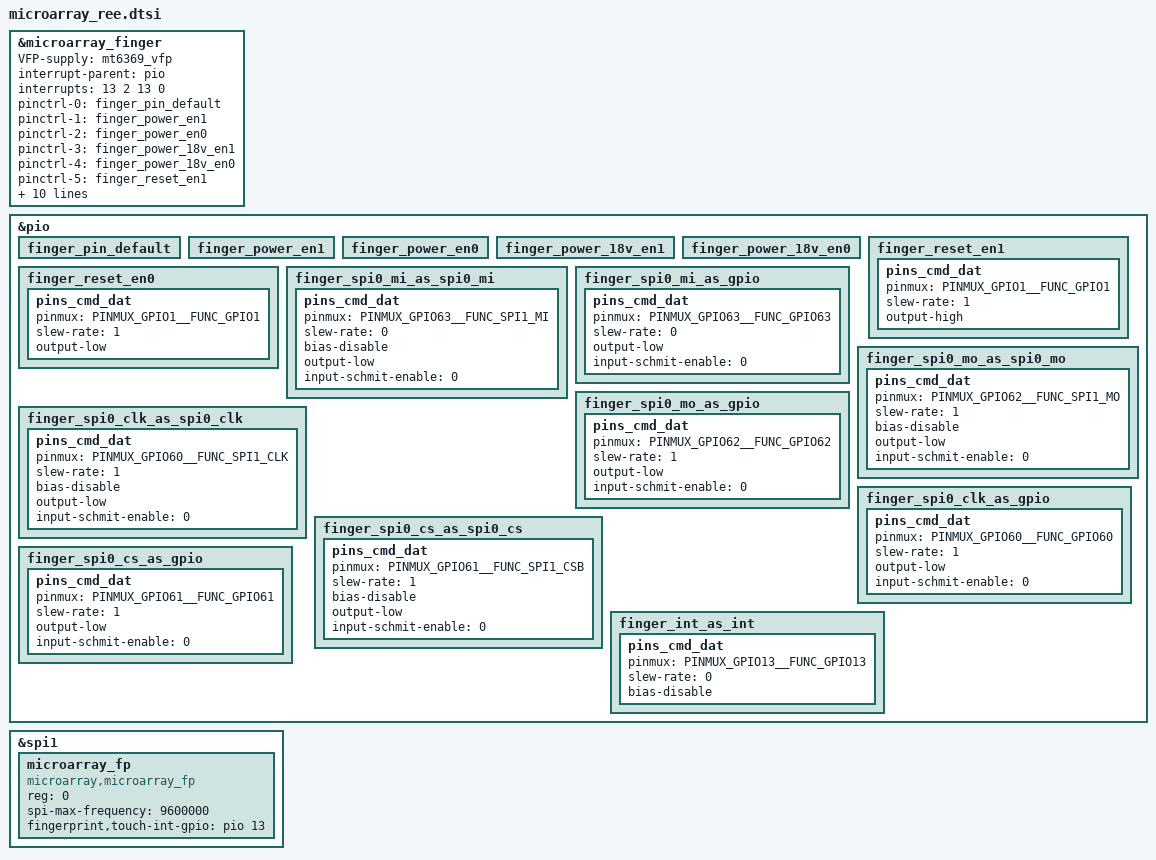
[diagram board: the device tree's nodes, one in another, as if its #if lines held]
#include "../../drv_common.h"

#if PRI_PLATFORM_MT6878
#include "./mt6878/custom.h"
#endif

/* microarray fingerprint ctrl start */

&microarray_finger {

		VFP-supply = <&mt6369_vfp>;
		interrupt-parent = <&pio>;
		interrupts = <13 2 13 0>;
		pinctrl-names = "default", "finger_power_en1", "finger_power_en0","finger_power_18v_en1","finger_power_18v_en0","finger_reset_en1","finger_reset_en0","finger_spi0_mi_as_spi0_mi","finger_spi0_mi_as_gpio","finger_spi0_mo_as_spi0_mo","finger_spi0_mo_as_gpio","finger_spi0_clk_as_spi0_clk","finger_spi0_clk_as_gpio","finger_spi0_cs_as_spi0_cs","finger_spi0_cs_as_gpio", "finger_int_as_int";
		pinctrl-0 = <&finger_pin_default>;
		pinctrl-1 = <&finger_power_en1>;
		pinctrl-2 = <&finger_power_en0>;
		pinctrl-3 = <&finger_power_18v_en1>;
		pinctrl-4 = <&finger_power_18v_en0>;
		pinctrl-5 = <&finger_reset_en1>;
		pinctrl-6 = <&finger_reset_en0>;
		pinctrl-7 = <&finger_spi0_mi_as_spi0_mi>;
		pinctrl-8 = <&finger_spi0_mi_as_gpio>;
		pinctrl-9 = <&finger_spi0_mo_as_spi0_mo>;
		pinctrl-10 = <&finger_spi0_mo_as_gpio>;
		pinctrl-11 = <&finger_spi0_clk_as_spi0_clk>;
		pinctrl-12 = <&finger_spi0_clk_as_gpio>;
		pinctrl-13 = <&finger_spi0_cs_as_spi0_cs>;
		pinctrl-14 = <&finger_spi0_cs_as_gpio>;
		pinctrl-15 = <&finger_int_as_int>;
		status = "okay";
};

&pio {
	finger_pin_default: finger_pin_default {
	};
	finger_power_en1: finger_power_en1 {

	};
	finger_power_en0: finger_power_en0 {
	};

	finger_power_18v_en1: finger_power_18v_en1 {
	};
	finger_power_18v_en0: finger_power_18v_en0 {
	};

	finger_reset_en1: finger_reset_en1 {
		pins_cmd_dat {
			pinmux = <PINMUX_GPIO1__FUNC_GPIO1>;
			slew-rate = <1>;
			output-high;
		};
	};
	finger_reset_en0: finger_reset_en0 {
		pins_cmd_dat {
			pinmux = <PINMUX_GPIO1__FUNC_GPIO1>;
			slew-rate = <1>;
			output-low;
		};
	};

	finger_spi0_mi_as_spi0_mi: finger_spi0_mi_as_spi0_mi {
		pins_cmd_dat {
			pinmux = <PINMUX_GPIO63__FUNC_SPI1_MI>;
			slew-rate = <0>;
			bias-disable;
			output-low;
			input-schmit-enable = <0>;
		};
	};
	finger_spi0_mi_as_gpio: finger_spi0_mi_as_gpio {
		pins_cmd_dat {
			pinmux = <PINMUX_GPIO63__FUNC_GPIO63>;
			slew-rate = <0>;
			output-low;
			input-schmit-enable = <0>;
		};
	};
	finger_spi0_mo_as_spi0_mo: finger_spi0_mo_as_spi0_mo {
		pins_cmd_dat {
			pinmux = <PINMUX_GPIO62__FUNC_SPI1_MO>;
			slew-rate = <1>;
			bias-disable;
			output-low;
			input-schmit-enable = <0>;
		};
	};
	finger_spi0_mo_as_gpio: finger_spi0_mo_as_gpio {
		pins_cmd_dat {
			pinmux = <PINMUX_GPIO62__FUNC_GPIO62>;
			slew-rate = <1>;
			output-low;
			input-schmit-enable = <0>;
		};
	};
	finger_spi0_clk_as_spi0_clk: finger_spi0_clk_as_spi0_clk {
		pins_cmd_dat {
			pinmux = <PINMUX_GPIO60__FUNC_SPI1_CLK>;
			slew-rate = <1>;
			bias-disable;
			output-low;
			input-schmit-enable = <0>;
		};
	};
	finger_spi0_clk_as_gpio: finger_spi0_clk_as_gpio {
		pins_cmd_dat {
			pinmux = <PINMUX_GPIO60__FUNC_GPIO60>;
			slew-rate = <1>;
			output-low;
			input-schmit-enable = <0>;
		};
	};
	finger_spi0_cs_as_spi0_cs: finger_spi0_cs_as_spi0_cs {
		pins_cmd_dat {
			pinmux = <PINMUX_GPIO61__FUNC_SPI1_CSB>;
			slew-rate = <1>;
			bias-disable;
			output-low;
			input-schmit-enable = <0>;
		};
	};
	finger_spi0_cs_as_gpio: finger_spi0_cs_as_gpio {
		pins_cmd_dat {
			pinmux = <PINMUX_GPIO61__FUNC_GPIO61>;
			slew-rate = <1>;
			output-low;
			input-schmit-enable = <0>;
		};
	};
	finger_int_as_int: finger_int_as_int {
		pins_cmd_dat {
			pinmux = <PINMUX_GPIO13__FUNC_GPIO13>;
                        slew-rate = <0>;
                        bias-disable;
		};
	};

};

&spi1 {
	#address-cells = <1>;     
	#size-cells = <0>;
 
    	microarray_fp:microarray_fp {
       		compatible = "microarray,microarray_fp";
       		reg = <0>;
       		spi-max-frequency = <9600000>;	
        	fingerprint,touch-int-gpio = <&pio 13 0>;
		
       		status = "okay";
    	}; 
};
/* microarray fingerprint ctrl end */
